# STM32F446 register map
File version: 1.9
CPU: CM4 r0p1, little endian, MPU, FPU, 4 interrupt priority bits
Registers are 32-bit, read-write, reset 0x0 unless marked. A register's access mark holds for its fields unless they carry their own. Offsets are from the block's base; [hi:lo] are bit positions; {n}, {i} and the like mark numbered series.

## TIM6 — Basic timers
Base 0x40001000
Same registers: TIM7 0x40001400
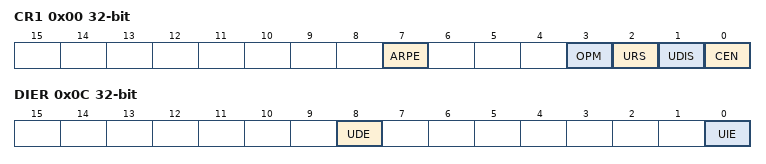
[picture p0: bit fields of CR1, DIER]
0x00 CR1 — control register 1
  [7] ARPE — Auto-reload preload enable
  [3] OPM — One-pulse mode
  [2] URS — Update request source
  [1] UDIS — Update disable
  [0] CEN — Counter enable
0x04 CR2 — control register 2
  [6:4] MMS — Master mode selection
0x0C DIER — DMA/Interrupt enable register
  [8] UDE — Update DMA request enable
  [0] UIE — Update interrupt enable
0x10 SR — status register
  [0] UIF — Update interrupt flag
0x14 EGR wo — event generation register
  [0] UG — Update generation
0x24 CNT — counter
  [15:0] CNT — Low counter value
0x28 PSC — prescaler
  [15:0] PSC — Prescaler value
0x2C ARR — auto-reload register
  [15:0] ARR — Low Auto-reload value

## CRC — Cryptographic processor
Base 0x40023000
0x00 DR reset 0xFFFFFFFF — Data register
  [31:0] DR — Data Register
0x04 IDR — Independent Data register
  [7:0] IDR
0x08 CR wo — Control register
  [0] CR — Control regidter

## OTG_FS_PWRCLK — USB on the go full speed
Base 0x50000E00
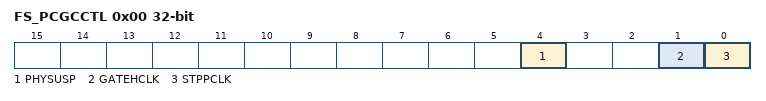
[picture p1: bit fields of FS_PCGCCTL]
0x00 FS_PCGCCTL — OTG_FS power and clock gating control register (OTG_FS_PCGCCTL)
  [4] PHYSUSP — PHY Suspended
  [1] GATEHCLK
  [0] STPPCLK — Stop PHY clock

## FLASH
Base 0x40023C00
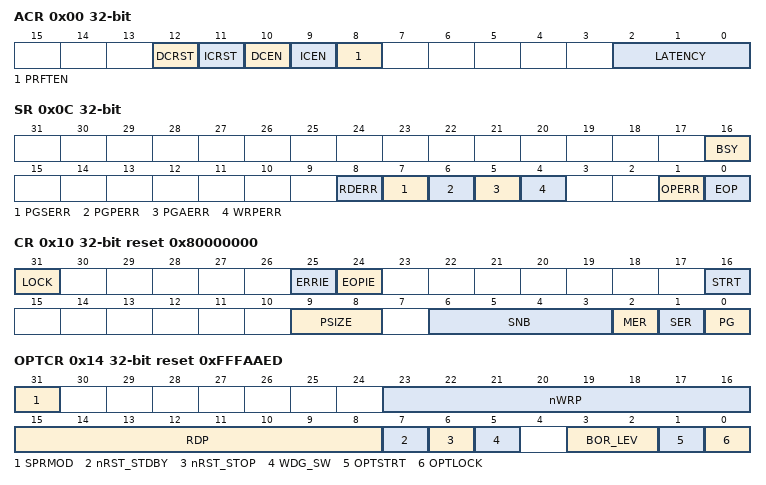
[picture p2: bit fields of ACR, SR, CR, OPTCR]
0x00 ACR access per field — Flash access control register
  [12] DCRST rw — Data cache reset
  [11] ICRST wo — Instruction cache reset
  [10] DCEN rw — Data cache enable
  [9] ICEN rw — Instruction cache enable
  [8] PRFTEN rw — Prefetch enable
  [2:0] LATENCY rw
0x04 KEYR wo — Flash key register
  [31:0] KEY — FPEC key
0x08 OPTKEYR wo — Flash option key register
  [31:0] OPTKEY — Option byte key
0x0C SR access per field — Status register
  [16] BSY ro — Busy
  [8] RDERR rw — Read Protection Error
  [7] PGSERR rw — Programming sequence error
  [6] PGPERR rw — Programming parallelism error
  [5] PGAERR rw — Programming alignment error
  [4] WRPERR rw — Write protection error
  [1] OPERR rw — Operation error
  [0] EOP rw — End of operation
0x10 CR reset 0x80000000 — Control register
  [31] LOCK
  [25] ERRIE — Error interrupt enable
  [24] EOPIE — End of operation interrupt enable
  [16] STRT — Start
  [9:8] PSIZE — Program size
  [6:3] SNB — Sector number
  [2] MER — Mass Erase of sectors 0 to 11
  [1] SER — Sector Erase
  [0] PG — Programming
0x14 OPTCR reset 0xFFFAAED — Flash option control register
  [31] SPRMOD — Selection of Protection Mode of nWPRi bits
  [23:16] nWRP — Not write protect
  [15:8] RDP — Read protect
  [7] nRST_STDBY — nRST_STDBY User option bytes
  [6] nRST_STOP — nRST_STOP User option bytes
  [5] WDG_SW — WDG_SW User option bytes
  [3:2] BOR_LEV — BOR reset Level
  [1] OPTSTRT — Option start
  [0] OPTLOCK — Option lock

## EXTI — External interrupt/event controller
Base 0x40013C00
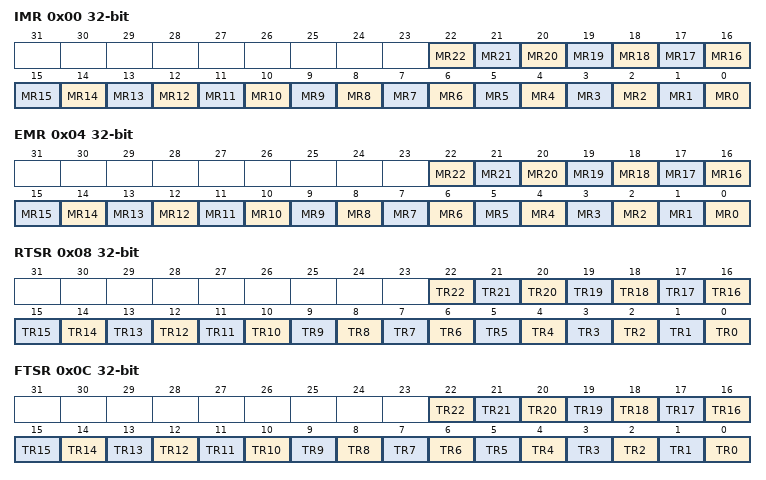
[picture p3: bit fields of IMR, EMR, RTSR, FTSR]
0x00 IMR — Interrupt mask register (EXTI_IMR)
  [n] MR{n} (n=0..22) — Interrupt Mask on line {n}
0x04 EMR — Event mask register (EXTI_EMR)
  [n] MR{n} (n=0..22) — Event Mask on line {n}
0x08 RTSR — Rising Trigger selection register (EXTI_RTSR)
  [n] TR{n} (n=0..22) — Rising trigger event configuration of line {n}
0x0C FTSR — Falling Trigger selection register (EXTI_FTSR)
  [n] TR{n} (n=0..22) — Falling trigger event configuration of line {n}
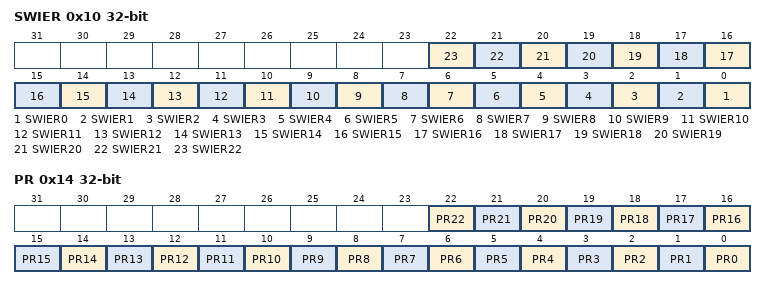
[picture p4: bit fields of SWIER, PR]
0x10 SWIER — Software interrupt event register (EXTI_SWIER)
  [n] SWIER{n} (n=0..22) — Software Interrupt on line {n}
0x14 PR — Pending register (EXTI_PR)
  [n] PR{n} (n=0..22) — Pending bit {n}

## OTG_HS_PWRCLK — USB on the go high speed
Base 0x40040E00
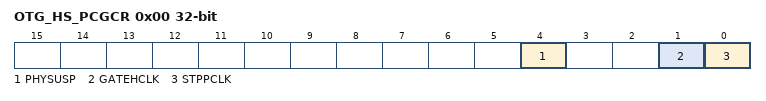
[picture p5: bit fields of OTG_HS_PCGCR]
0x00 OTG_HS_PCGCR — Power and clock gating control register
  [4] PHYSUSP — PHY suspended
  [1] GATEHCLK
  [0] STPPCLK — Stop PHY clock

## Notices in the file
Copyright (c) 2024 STMicroelectronics.
SPDX-License-Identifier: Apache-2.0
Licensed under the Apache License, Version 2.0 (the "License");
you may not use this file except in compliance with the License.
You may obtain a copy of the License at
http://www.apache.org/licenses/LICENSE-2.0
Unless required by applicable law or agreed to in writing, software
distributed under the License is distributed on an "AS IS" BASIS,
WITHOUT WARRANTIES OR CONDITIONS OF ANY KIND, either express or implied.
See the License for the specific language governing permissions and
limitations under the License.
